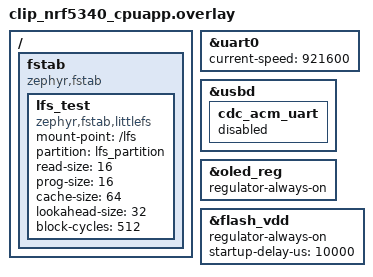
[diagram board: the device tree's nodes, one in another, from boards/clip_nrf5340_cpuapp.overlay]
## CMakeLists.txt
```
#
# Copyright (c) 2022 Nordic Semiconductor ASA
#
# SPDX-License-Identifier: LicenseRef-Nordic-5-Clause
#

cmake_minimum_required(VERSION 3.20.0)

# The test uses the repository's custom gpio-button devicetree binding.
list(APPEND DTS_ROOT ${CMAKE_CURRENT_LIST_DIR}/../..)

find_package(Zephyr REQUIRED HINTS $ENV{ZEPHYR_BASE})
project(clip)

target_sources(app PRIVATE
	src/main.c
	src/ble.c
	src/wifi.c
	src/button.c
	src/sdcard.c
	src/mic.c
	src/oled.c
	src/pmic.c
	src/motor.c
	src/usb.c
	src/identity.c
	src/flash_test.c
	src/sn_prog.c
	src/swd_ctrl.c
	# The test image builds the CH1115 driver directly. CONFIG_OLED_DISPLAY is
	# deliberately disabled in prj.conf to prevent the module from adding the
	# same source a second time.
	${CMAKE_CURRENT_LIST_DIR}/../../drivers/display/ch1115.c
)
```

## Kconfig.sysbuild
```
#
# Copyright (c) 2023 Nordic Semiconductor
#
# SPDX-License-Identifier: LicenseRef-Nordic-5-Clause
#

source "${ZEPHYR_BASE}/share/sysbuild/Kconfig"

config NRF_DEFAULT_IPC_RADIO
	default y

config NETCORE_IPC_RADIO_BT_HCI_IPC
	default y
```

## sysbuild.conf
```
#
# Copyright (c) 2024 Nordic Semiconductor ASA
#
# SPDX-License-Identifier: LicenseRef-Nordic-5-Clause
#

# Enable WiFi nRF70
SB_CONFIG_WIFI_NRF70=y
```

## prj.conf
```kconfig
#
# Copyright (c) 2023 Nordic Semiconductor ASA
#
# SPDX-License-Identifier: LicenseRef-Nordic-5-Clause
#

# DMIC (Digital Microphone)
CONFIG_AUDIO=y
CONFIG_AUDIO_DMIC=y

# SD Card and File System
CONFIG_DISK_ACCESS=y
CONFIG_DISK_DRIVER_SDMMC=y
CONFIG_FILE_SYSTEM=y
CONFIG_FAT_FILESYSTEM_ELM=y
CONFIG_FS_FATFS_LFN=y
CONFIG_FS_FATFS_MKFS=y
CONFIG_FILE_SYSTEM_MKFS=y

# SPI Flash
CONFIG_FLASH=y
CONFIG_FLASH_MAP=y

# WiFi AP mode
CONFIG_WIFI=y
CONFIG_WIFI_NRF70=y
CONFIG_NRF70_AP_MODE=y
CONFIG_WIFI_NM_WPA_SUPPLICANT=y
CONFIG_WIFI_NM_WPA_SUPPLICANT_AP=y
CONFIG_WIFI_NM_WPA_SUPPLICANT_LOG_LEVEL_INF=n
CONFIG_WIFI_RANDOM_MAC_ADDRESS=y

# WiFi and BLE coexistence
CONFIG_NRF70_SR_COEX=y
CONFIG_NRF_WIFI_IF_AUTO_START=n
CONFIG_NRF70_QSPI_LOW_POWER=y

# WiFi ready callback (for runtime net_if_up)
CONFIG_WIFI_READY_LIB=y

# Shared antenna configuration (not separate antennas)
CONFIG_COEX_SEP_ANTENNAS=n

# SR protocol is BLE
CONFIG_SR_PROTOCOL_BLE=y

# Reduce memory usage - fewer buffers
CONFIG_NRF70_RX_NUM_BUFS=8
CONFIG_NRF70_MAX_TX_AGGREGATION=2

# WiFi credentials - not needed for AP mode
CONFIG_WIFI_CREDENTIALS=n

# Disable WPA3/SAE - WPA2-PSK only (v3.3.0: WPA3 is now a choice)
CONFIG_WIFI_NM_WPA_SUPPLICANT_WPA3_IMPLEMENTATION_NONE=y

# WiFi memory
CONFIG_NRF_WIFI_CTRL_HEAP_SIZE=20000
CONFIG_NRF_WIFI_DATA_HEAP_SIZE=53000
CONFIG_WIFI_NM_WPA_SUPPLICANT_THREAD_STACK_SIZE=10240

# zperf for throughput testing
CONFIG_NET_ZPERF=y

# Networking Management API
CONFIG_NET_MGMT=y
CONFIG_NET_MGMT_EVENT=y

# AP static IP
CONFIG_NET_CONFIG_SETTINGS=y
CONFIG_NET_CONFIG_INIT_TIMEOUT=0
CONFIG_NET_CONFIG_MY_IPV4_ADDR="192.168.4.1"
CONFIG_NET_CONFIG_MY_IPV4_NETMASK="255.255.255.0"
CONFIG_NET_CONFIG_MY_IPV4_GW="192.168.4.1"

# DHCP server for AP clients
CONFIG_NET_DHCPV4=y
CONFIG_NET_DHCPV4_SERVER=y
CONFIG_NET_DHCPV4_SERVER_ADDR_COUNT=1

# Shell - minimal
CONFIG_SHELL=y
CONFIG_SHELL_BACKEND_SERIAL=y
CONFIG_NET_SHELL=n
CONFIG_WIFI_CREDENTIALS_SHELL=n
CONFIG_NET_L2_WIFI_SHELL=n

# Filesystem shell commands
CONFIG_FILE_SYSTEM_SHELL=y

# Regulator shell commands
# (CONFIG_FLASH_SHELL intentionally off: it registers a built-in `flash` root
#  command that collides with flash_test.c's `flash`/`flash speed`/`flash test`.)
CONFIG_REGULATOR=y
CONFIG_REGULATOR_SHELL=y
CONFIG_GPIO_SHELL=y

# Device power management
CONFIG_PM_DEVICE=y
CONFIG_PM_DEVICE_RUNTIME=y
CONFIG_TICKLESS_KERNEL=y
CONFIG_POWEROFF=y

# Sensor (for PMIC battery/charger monitoring)
CONFIG_SENSOR=y

# nRF Fuel Gauge: use the same profiled rechargeable-cell model as the
# production Clip firmware rather than a voltage-only lookup table.
CONFIG_NRF_FUEL_GAUGE=y
CONFIG_NRF_FUEL_GAUGE_VARIANT_SECONDARY_CELL=y

# Persist the fuel-gauge state on external-flash LittleFS. This keeps the
# displayed SoC continuous through reset / SYSTEM OFF instead of re-estimating
# it from a relaxed battery voltage on every boot.
CONFIG_FILE_SYSTEM_LITTLEFS=y
CONFIG_FS_LITTLEFS_FMP_DEV=y
CONFIG_FS_LITTLEFS_FC_HEAP_SIZE=4096
CONFIG_FS_LITTLEFS_NUM_FILES=16
CONFIG_FS_LITTLEFS_NUM_DIRS=4
CONFIG_SETTINGS=y
CONFIG_SETTINGS_FILE=y
CONFIG_SETTINGS_FILE_PATH="/lfs/settings/run"
CONFIG_SETTINGS_FILE_MAX_LINES=16


# I2C and I2C shell commands
CONFIG_I2C=y
CONFIG_I2C_SHELL=y

# Shell stack size - increased for WiFi operations
CONFIG_SHELL_STACK_SIZE=4096

# Logging - increased buffer to prevent message drops
CONFIG_LOG=y
CONFIG_LOG_DEFAULT_LEVEL=3
CONFIG_LOG_BACKEND_UART=y
CONFIG_LOG_BACKEND_RTT=n
CONFIG_LOG_BUFFER_SIZE=4096

# System settings
CONFIG_NEWLIB_LIBC=y
CONFIG_NEWLIB_LIBC_NANO=n

# Minimal networking - UDP only
CONFIG_NETWORKING=y
CONFIG_NET_SOCKETS=y
CONFIG_NET_SOCKETS_POLL_MAX=4
CONFIG_NET_L2_ETHERNET=y
CONFIG_NET_L2_WIFI_MGMT=y
CONFIG_NET_IPV4=y
CONFIG_NET_IPV6=n
CONFIG_NET_UDP=y
CONFIG_NET_TCP=n

# mbedTLS - use nRF security library instead of builtin
CONFIG_MBEDTLS=y
CONFIG_MBEDTLS_LEGACY_CRYPTO_C=n

# Memory optimization - reduced for RAM efficiency
CONFIG_SYSTEM_WORKQUEUE_STACK_SIZE=6144
CONFIG_MAIN_STACK_SIZE=6144

# Heap size for WiFi/crypto operations
CONFIG_HEAP_MEM_POOL_SIZE=120000

CONFIG_MBEDTLS_HEAP_SIZE=1024

# Network buffers (balanced for stability)
CONFIG_NET_TC_TX_COUNT=2
CONFIG_NET_BUF_TX_COUNT=14
CONFIG_NET_BUF_RX_COUNT=14
CONFIG_NET_PKT_TX_COUNT=6
CONFIG_NET_PKT_RX_COUNT=6
CONFIG_NET_TX_STACK_SIZE=4096
CONFIG_NET_RX_STACK_SIZE=4096

CONFIG_NET_BUF_FIXED_DATA_SIZE=y
CONFIG_NET_BUF_DATA_SIZE=512

# DHCP
CONFIG_NET_DHCPV4=y

CONFIG_WIFI_RANDOM_MAC_ADDRESS=y
CONFIG_BT=y
CONFIG_BT_PERIPHERAL=y
CONFIG_BT_DEVICE_NAME="Clip_Test"
CONFIG_BT_DEVICE_NAME_DYNAMIC=y
CONFIG_BT_MAX_CONN=1
CONFIG_BT_SMP=y
CONFIG_BT_GATT_CLIENT=y

# BLE throughput optimization
CONFIG_BT_BUF_ACL_RX_SIZE=251
CONFIG_BT_BUF_ACL_TX_SIZE=251
CONFIG_BT_L2CAP_TX_MTU=247

# Increase thread priority for BLE operations
CONFIG_BT_RX_STACK_SIZE=2048

# Display support (OLED CH1115)
CONFIG_DISPLAY=y
CONFIG_GPIO=y
# The test CMakeLists compiles this custom driver explicitly. Do not also
# compile the module library, otherwise ch1115.c is linked twice.
CONFIG_OLED_DISPLAY=n

# USB Mass Storage (expose SD card as USB drive)
CONFIG_USB_DEVICE_STACK_NEXT=y
CONFIG_USBD_MSC_CLASS=y
CONFIG_USBD_MSC_LUNS_PER_INSTANCE=1
CONFIG_USBD_MSC_DOUBLE_BUFFERING=n
CONFIG_USBD_MSC_SCSI_BUFFER_SIZE=512
CONFIG_HWINFO=y

# Reboot command
CONFIG_REBOOT=y

# SN programming tool CRC (sn_prog.c)
CONFIG_CRC=y
```

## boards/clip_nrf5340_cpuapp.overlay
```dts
/*
 * Copyright (c) 2023 Nordic Semiconductor ASA
 *
 * SPDX-License-Identifier: LicenseRef-Nordic-5-Clause
 */

/* UART configuration for 921600 baud rate */
&uart0 {
	current-speed = <921600>;
};

/* Enable USB device for MSC only */
&usbd {
	status = "okay";
	cdc_acm_uart {
		status = "disabled";
	};
};

/* The CH1115 driver has no vin-supply phandle. Keep its GPIO supply asserted
 * for the entire hardware-test session so it cannot be disabled as an unused
 * regulator before the persistent battery screen starts updating. */
&oled_reg {
	regulator-always-on;
};

/* SPI flash power (P0.27). With CONFIG_PM_DEVICE_RUNTIME the boot-on regulator
 * gets runtime-suspended before spi_nor probes the chip -> JEDEC read fails ->
 * "SPI flash not ready" + LittleFS mount fails (-19). Keep it asserted for the
 * whole test session. */
&flash_vdd {
	regulator-always-on;
	/* Unlike applications/clip (which runs under MCUboot, and MCUboot reads
	 * the app image from this flash so the chip is already powered/settled by
	 * the time the app probes it), this no-MCUboot image probes the flash at
	 * boot within microseconds of asserting VDD -> JEDEC read returns 00 00 00
	 * (chip still in power-on reset, tPUW ~10 ms). Wait it out. */
	startup-delay-us = <10000>;
};

/ {
	/* Point the generic filesystem shell at the external LittleFS partition.
	 * The test image has Partition Manager disabled, so its partition node is
	 * named lfs_partition (the production PM-generated alias is unavailable). */
	fstab {
		compatible = "zephyr,fstab";

		lfs_test: lfs_test {
			compatible = "zephyr,fstab,littlefs";
			mount-point = "/lfs";
			partition = <&lfs_partition>;
			read-size = <16>;
			prog-size = <16>;
			cache-size = <64>;
			lookahead-size = <32>;
			block-cycles = <512>;
		};
	};
};
```

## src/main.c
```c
/*
 * Copyright (c) 2023 Nordic Semiconductor ASA
 *
 * SPDX-License-Identifier: LicenseRef-Nordic-5-Clause
 */

#include <stdio.h>
#include <stdlib.h>
#include <zephyr/kernel.h>
#include <zephyr/logging/log.h>
#include <zephyr/sys/printk.h>
#include <zephyr/sys/reboot.h>
#include <zephyr/sys/poweroff.h>
#include <zephyr/shell/shell.h>
#include <zephyr/device.h>
#include <zephyr/drivers/gpio.h>
#include <zephyr/drivers/regulator.h>
#include <zephyr/pm/device.h>
#include <zephyr/storage/disk_access.h>
#include <zephyr/bluetooth/bluetooth.h>
#include <zephyr/dt-bindings/regulator/npm13xx.h>
#include <nrfx_clock.h>
#include <hal/nrf_oscillators.h>
#include "wifi.h"
#include "ble.h"
#include "button.h"
#include "sdcard.h"
#include "mic.h"
#include "oled.h"
#include "pmic.h"
#include "motor.h"
#include "usb.h"

LOG_MODULE_REGISTER(main, LOG_LEVEL_INF);

/* This image has no MCUboot (SB_CONFIG_BOOTLOADER_NONE), unlike applications/
 * clip where MCUboot accesses the external SPI flash first and so has already
 * driven flash_vdd high + woken the chip before the app probes it. Here
 * spi_nor (POST_KERNEL prio 80) is the first access, and with
 * CONFIG_PM_DEVICE_RUNTIME_ASYNC the boot-on regulator enable is deferred, so
 * the GPIO hasn't been driven yet -> JEDEC read returns 00 00 00. Force the
 * regulator on and block long enough (tPUW ~10 ms) for the chip to settle,
 * BEFORE spi_nor runs. */
static int flash_vdd_preinit(void)
{
	const struct device *fv = DEVICE_DT_GET(DT_NODELABEL(flash_vdd));
	if (device_is_ready(fv)) {
		(void)regulator_enable(fv);
	}
	k_msleep(50);
	return 0;
}
SYS_INIT(flash_vdd_preinit, POST_KERNEL, 78);

static int cmd_reboot(const struct shell *sh, size_t argc, char **argv)
{
	ARG_UNUSED(argc);
	ARG_UNUSED(argv);

	shell_print(sh, "Rebooting...");
	(void)pmic_battery_state_save();
	k_sleep(K_MSEC(100));
	sys_reboot(SYS_REBOOT_WARM);
	return 0;
}

SHELL_CMD_REGISTER(reboot, NULL, "Reboot device", cmd_reboot);

struct sd_shutdown_result {
	int unmount_rc;
	int deinit_rc;
	int suspend_rc;
	int cs_rc;
	int ldo_rc;
	bool ldo_before;
	bool ldo_after;
};

static struct sd_shutdown_result sys_sd_shutdown(void);
static void sys_wifi_power_off(void);

/* The fuel gauge is software state. Save it before any SYSTEM OFF path so a
 * relaxed cell voltage after wake cannot make the always-on OLED jump. */
static void sys_poweroff_with_battery_state(void)
{
	int ret = pmic_battery_state_save();

	if (ret != 0 && ret != -EAGAIN) {
		LOG_WRN("Fuel-gauge state save before power-off failed: %d", ret);
	}
	sys_poweroff();
}

/* cmd_sys_stop is defined after the device pointers below (it touches all of
 * them for a full shutdown). */

/* Isolate the UART contribution before SYSTEM OFF. The production Clip build
 * saves about 570 uA by disabling UART console/logging. */
static const struct device *const uart0 = DEVICE_DT_GET(DT_NODELABEL(uart0));

static int cmd_sys_uart_stop(const struct shell *sh, size_t argc, char **argv)
{
	ARG_UNUSED(argc);
	ARG_UNUSED(argv);

	shell_print(sh, "Suspending UARTE, then entering nRF5340 SYSTEM OFF");
	k_sleep(K_MSEC(100));
	(void)pm_device_action_run(uart0, PM_DEVICE_ACTION_SUSPEND);
	sys_poweroff_with_battery_state();
	return 0;
}

/* nRF7002 is powered by two board GPIOs; leave all data/coexistence pins
 * untouched here so this command isolates only the radio supply domains. */
static const struct device *const gpio0 = DEVICE_DT_GET(DT_NODELABEL(gpio0));
static const struct device *const gpio1 = DEVICE_DT_GET(DT_NODELABEL(gpio1));
static const struct device *const i2c2 = DEVICE_DT_GET(DT_NODELABEL(i2c2));
static const struct device *const spi4 = DEVICE_DT_GET(DT_NODELABEL(spi4));
static const struct device *const npm1300 = DEVICE_DT_GET(DT_NODELABEL(npm1300));
static const struct device *const npm1300_regulators =
	DEVICE_DT_GET(DT_NODELABEL(npm1300_regulators));
static const struct device *const ldo1 = DEVICE_DT_GET(DT_NODELABEL(npm1300_ldo1));
static const struct device *const ldo2 = DEVICE_DT_GET(DT_NODELABEL(npm1300_ldo2));

/* nRF7002 supply domains: this is the same proven isolation sequence used by
 * `sys wifi_stop`, which removes about 70 uA before SYSTEM OFF. */
static void sys_wifi_power_off(void)
{
	(void)gpio_pin_configure(gpio0, 11, GPIO_OUTPUT_INACTIVE); /* BUCKEN */
	(void)gpio_pin_configure(gpio0, 26, GPIO_OUTPUT_INACTIVE); /* IOVDD_EN */
	(void)gpio_pin_configure(gpio0, 29, GPIO_OUTPUT_INACTIVE); /* RF switch */
}

/* Keep every SD signal benign before cutting VDD_SD. SPI4's sleep pinctrl
 * parks SCK/MOSI/MISO low, and CS is then explicitly pulled low. */
static struct sd_shutdown_result sys_sd_shutdown(void)
{
	struct sd_shutdown_result result;

	result.ldo_before = regulator_is_enabled(ldo2);
	result.unmount_rc = sdcard_unmount();
	result.deinit_rc = disk_access_ioctl("SD", DISK_IOCTL_CTRL_DEINIT, NULL);
	result.suspend_rc = pm_device_action_run(spi4, PM_DEVICE_ACTION_SUSPEND);
	result.cs_rc = gpio_pin_configure(gpio0, 9, GPIO_INPUT | GPIO_PULL_DOWN);
	result.ldo_rc = regulator_disable(ldo2);
	result.ldo_after = regulator_is_enabled(ldo2);

	return result;
}

static void print_device_state(const struct shell *sh, const char *name,
			       const struct device *dev)
{
	shell_print(sh, "%s: ready=%d init=%d init_res=-%u", name,
		    device_is_ready(dev), dev->state->initialized, dev->state->init_res);
}

static int cmd_sys_sd_status(const struct shell *sh, size_t argc, char **argv)
{
	ARG_UNUSED(argc);
	ARG_UNUSED(argv);

	print_device_state(sh, "nPM1300", npm1300);
	print_device_state(sh, "nPM1300 regulators", npm1300_regulators);
	print_device_state(sh, "LDO1", ldo1);
	print_device_state(sh, "LDO2", ldo2);
	print_device_state(sh, "SPI4", spi4);
	return 0;
}

static int cmd_sys_sd_stop(const struct shell *sh, size_t argc, char **argv)
{
	struct sd_shutdown_result result;

	ARG_UNUSED(argc);
	ARG_UNUSED(argv);

	result = sys_sd_shutdown();

	shell_print(sh, "SD shutdown: ldo %d -> %d", result.ldo_before, result.ldo_after);
	shell_print(sh, "  unmount=%d deinit=%d spi4_suspend=%d cs=%d ldo2_disable=%d",
		    result.unmount_rc, result.deinit_rc, result.suspend_rc,
		    result.cs_rc, result.ldo_rc);
	shell_print(sh, "Entering nRF5340 SYSTEM OFF");
	k_sleep(K_MSEC(200));
	sys_poweroff_with_battery_state();
	return 0;
}

static int cmd_sys_wifi_stop(const struct shell *sh, size_t argc, char **argv)
{
	ARG_UNUSED(argc);
	ARG_UNUSED(argv);

	shell_print(sh, "Cutting nRF7002 power, then entering nRF5340 SYSTEM OFF");
	k_sleep(K_MSEC(100));
	sys_wifi_power_off();
	sys_poweroff_with_battery_state();
	return 0;
}

static int cmd_sys_oled_stop(const struct shell *sh, size_t argc, char **argv)
{
	ARG_UNUSED(argc);
	ARG_UNUSED(argv);

	shell_print(sh, "Isolating OLED bus, cutting VDD, then entering SYSTEM OFF");
	k_sleep(K_MSEC(100));
	/* Do not leave any OLED input high when VDD is removed: it back-powers
	 * the display through its ESD diodes. */
	(void)pm_device_action_run(i2c2, PM_DEVICE_ACTION_SUSPEND);
	(void)gpio_pin_configure(gpio1, 9, GPIO_OUTPUT_INACTIVE); /* RESET asserted */
	(void)gpio_pin_configure(gpio1, 8, GPIO_OUTPUT_INACTIVE); /* OLED VDD */
	sys_poweroff_with_battery_state();
	return 0;
}

static int cmd_sys_mic_stop(const struct shell *sh, size_t argc, char **argv)
{
	int ret;

	ARG_UNUSED(argc);
	ARG_UNUSED(argv);

	if (!device_is_ready(ldo1)) {
		shell_error(sh, "nPM1300 LDO1 is not ready");
		return -ENODEV;
	}

	shell_print(sh, "Cutting microphone LDO1, then entering SYSTEM OFF");
	ret = regulator_disable(ldo1);
	if (ret != 0) {
		shell_error(sh, "LDO1 disable failed: %d", ret);
		return ret;
	}

	k_sleep(K_MSEC(100));
	sys_poweroff_with_battery_state();
	return 0;
}

static int cmd_sys_ble_stop(const struct shell *sh, size_t argc, char **argv)
{
	int ret;

	ARG_UNUSED(argc);
	ARG_UNUSED(argv);

	shell_print(sh, "Stopping BLE, then entering nRF5340 SYSTEM OFF");
	ret = bt_le_adv_stop();
	if (ret != 0 && ret != -EALREADY) {
		shell_warn(sh, "BLE advertising stop failed: %d", ret);
	}

	ret = bt_disable();
	if (ret != 0) {
		/* The IPC controller may already be unavailable. Do not let a failed
		 * HCI reset prevent the following SYSTEM OFF current measurement. */
		shell_warn(sh, "BLE disable failed: %d; continuing to SYSTEM OFF", ret);
	}

	k_sleep(K_MSEC(100));
	sys_poweroff_with_battery_state();
	return 0;
}

static const struct device *const buck2 = DEVICE_DT_GET(DT_NODELABEL(npm1300_buck2));

static int cmd_sys_buck_pfm_stop(const struct shell *sh, size_t argc, char **argv)
{
	int ret;

	ARG_UNUSED(argc);
	ARG_UNUSED(argv);

	if (!device_is_ready(buck2)) {
		shell_error(sh, "nPM1300 BUCK2 is not ready");
		return -ENODEV;
	}

	shell_print(sh, "Setting BUCK2 PFM, then entering SYSTEM OFF");
	ret = regulator_set_mode(buck2, NPM13XX_BUCK_MODE_PFM);
	if (ret != 0) {
		shell_error(sh, "BUCK2 PFM failed: %d", ret);
		return ret;
	}

	k_sleep(K_MSEC(100));
	sys_poweroff_with_battery_state();
	return 0;
}

/* Full shutdown: stop every peripheral known to leak or hold a wake source,
 * THEN suspend the UART (~570 uA console leak) and enter SYSTEM OFF. Use this
 * (not the single-peripheral `sys *_stop` isolation commands) to measure sleep
 * current. NOTE: with SWD/J-Link attached, nRF5340 cannot enter true SYSTEM
 * OFF — detach the probe and power-cycle to read uA-level current. */
static int cmd_sys_stop(const struct shell *sh, size_t argc, char **argv)
{
	struct sd_shutdown_result sd;
	int ret;

	ARG_UNUSED(argc);
	ARG_UNUSED(argv);

	shell_print(sh, "Full peripheral shutdown, then nRF5340 SYSTEM OFF");

	/* 1. Stop the 1 s battery/OLED refresh work — otherwise it keeps waking
	 * the CPU every second and writing to the bus/display being shut down. */
	shell_print(sh, "  [1/9] Stop 1s battery/OLED refresh work: %d",
		    pmic_display_work_stop());

	/* 2. BLE / network-core radio (wake source) */
	shell_print(sh, "  [2/9] BLE: adv stop + disable");
	ret = bt_le_adv_stop();
	if (ret != 0 && ret != -EALREADY) {
		shell_warn(sh, "    adv stop: %d", ret);
	}
	(void)bt_disable();

	/* 3. nRF7002 WiFi supply (~70 uA) */
	shell_print(sh, "  [3/9] WiFi: nRF7002 power off");
	sys_wifi_power_off();

	/* 4. USB device (wake source when VBUS present) */
	shell_print(sh, "  [4/9] USB: disable");
	(void)usb_msc_disable();

	/* 5. SD card + LDO2 */
	shell_print(sh, "  [5/9] SD: unmount + SPI4 suspend + LDO2 off");
	sd = sys_sd_shutdown();
	if (sd.ldo_after) {
		shell_warn(sh, "    LDO2 still on (unmount=%d deinit=%d spi4=%d cs=%d ldo=%d)",
			   sd.unmount_rc, sd.deinit_rc, sd.suspend_rc, sd.cs_rc, sd.ldo_rc);
	}

	/* 6. Mic LDO1 */
	shell_print(sh, "  [6/9] Mic: LDO1 off");
	if (device_is_ready(ldo1)) {
		(void)regulator_disable(ldo1);
	}

	/* 7. OLED (bus suspend + VDD/RESET low to avoid ESD back-power) */
	shell_print(sh, "  [7/9] OLED: bus suspend + VDD off");
	(void)pm_device_action_run(i2c2, PM_DEVICE_ACTION_SUSPEND);
	(void)gpio_pin_configure(gpio1, 9, GPIO_OUTPUT_INACTIVE);  /* RESET */
	(void)gpio_pin_configure(gpio1, 8, GPIO_OUTPUT_INACTIVE);  /* OLED VDD */

	/* 8. BUCK2 PFM (low-power regulator mode) */
	shell_print(sh, "  [8/9] BUCK2: PFM");
	if (device_is_ready(buck2)) {
		(void)regulator_set_mode(buck2, NPM13XX_BUCK_MODE_PFM);
	}

	/* 9. UART console (~570 uA) — suspended LAST so the shell stays up until
	 * the final message is flushed. */
	shell_print(sh, "  [9/9] UART: suspend (console goes dark) -> SYSTEM OFF");
	k_sleep(K_MSEC(300));  /* let the last line flush before UARTE dies */
	(void)pm_device_action_run(uart0, PM_DEVICE_ACTION_SUSPEND);

	sys_poweroff_with_battery_state();
	return 0;
}

SHELL_STATIC_SUBCMD_SET_CREATE(sub_sys_cmds,
	SHELL_CMD(stop, NULL, "Full shutdown (all peripherals) then SYSTEM OFF", cmd_sys_stop),
	SHELL_CMD(uart_stop, NULL, "Suspend UARTE then system power off", cmd_sys_uart_stop),
	SHELL_CMD(wifi_stop, NULL, "Cut nRF7002 power then system power off", cmd_sys_wifi_stop),
	SHELL_CMD(oled_stop, NULL, "Cut OLED VDD then system power off", cmd_sys_oled_stop),
	SHELL_CMD(mic_stop, NULL, "Cut microphone LDO1 then system power off", cmd_sys_mic_stop),
	SHELL_CMD(ble_stop, NULL, "Stop BLE then system power off", cmd_sys_ble_stop),
	SHELL_CMD(buck_pfm_stop, NULL, "Set BUCK2 PFM then system power off", cmd_sys_buck_pfm_stop),
	SHELL_CMD(sd_status, NULL, "Show SD/PMIC device initialization state", cmd_sys_sd_status),
	SHELL_CMD(sd_stop, NULL, "Log SD shutdown steps then system power off", cmd_sys_sd_stop),
);

SHELL_CMD_REGISTER(sys, &sub_sys_cmds, "System power control", NULL);

/* LFXO capacitance commands */
static const char *lfxo_cap_name(uint32_t val)
{
	switch (val) {
	case 0: return "External";
	case 1: return "6 pF";
	case 2: return "7 pF";
	case 3: return "9 pF";
	default: return "Unknown";
	}
}

static int cmd_lfxo_cap_get(const struct shell *sh, size_t argc, char **argv)
{
	ARG_UNUSED(argc);
	ARG_UNUSED(argv);

	uint32_t cap = NRF_OSCILLATORS->XOSC32KI.INTCAP;
	shell_print(sh, "LFXO capacitance: %u (%s)", cap, lfxo_cap_name(cap));
	return 0;
}

static int cmd_lfxo_cap_set(const struct shell *sh, size_t argc, char **argv)
{
	if (argc < 2) {
		shell_print(sh, "Usage: lfxo cap <0-3>");
		shell_print(sh, "  0 = External capacitors");
		shell_print(sh, "  1 = 6 pF internal");
		shell_print(sh, "  2 = 7 pF internal");
		shell_print(sh, "  3 = 9 pF internal");
		return -EINVAL;
	}

	int val = atoi(argv[1]);
	if (val < 0 || val > 3) {
		shell_print(sh, "Error: value must be 0-3");
		return -EINVAL;
	}

	NRF_OSCILLATORS->XOSC32KI.INTCAP = (uint32_t)val;
	shell_print(sh, "LFXO capacitance set to: %u (%s)", val, lfxo_cap_name(val));
	return 0;
}

SHELL_STATIC_SUBCMD_SET_CREATE(sub_lfxo_cap,
	SHELL_CMD(get, NULL, "Get LFXO capacitance", cmd_lfxo_cap_get),
	SHELL_CMD_ARG(set, NULL, "Set LFXO capacitance (0-3)", cmd_lfxo_cap_set, 2, 0),
	SHELL_SUBCMD_SET_END
);

SHELL_CMD_REGISTER(lfxo, &sub_lfxo_cap, "LFXO 32.768kHz crystal capacitance", NULL);

/* HFXO capacitance commands */
static int cmd_hfxo_cap_get(const struct shell *sh, size_t argc, char **argv)
{
	ARG_UNUSED(argc);
	ARG_UNUSED(argv);

	uint32_t reg = NRF_OSCILLATORS->XOSC32MCAPS;
	bool enabled = (reg & OSCILLATORS_XOSC32MCAPS_ENABLE_Msk) != 0;
	uint32_t capvalue = (reg & OSCILLATORS_XOSC32MCAPS_CAPVALUE_Msk)
		>> OSCILLATORS_XOSC32MCAPS_CAPVALUE_Pos;

	if (enabled) {
		shell_print(sh, "HFXO capacitance: internal (CAPVALUE=%u)", capvalue);
	} else {
		shell_print(sh, "HFXO capacitance: external");
	}
	return 0;
}

static int cmd_hfxo_cap_set(const struct shell *sh, size_t argc, char **argv)
{
	if (argc < 2) {
		shell_print(sh, "Usage: hfxo set <picofarad>");
		shell_print(sh, "  Range: 7.0 - 20.0 pF, step 0.5 pF");
		shell_print(sh, "  Example: hfxo set 9.5");
		shell_print(sh, "  Use 0 to disable (external capacitors)");
		return -EINVAL;
	}

	float pf = strtof(argv[1], NULL);
	if (pf == 0.0f) {
		NRF_OSCILLATORS->XOSC32MCAPS =
			OSCILLATORS_XOSC32MCAPS_ENABLE_Disabled <<
			OSCILLATORS_XOSC32MCAPS_ENABLE_Pos;
		shell_print(sh, "HFXO capacitance: external");
		return 0;
	}

	if (pf < 7.0f || pf > 20.0f) {
		shell_print(sh, "Error: value must be 7.0-20.0 pF or 0 for external");
		return -EINVAL;
	}

	uint32_t capvalue = NRF_OSCILLATORS_HFXO_CAP_CALCULATE(NRF_FICR, pf);
	NRF_OSCILLATORS->XOSC32MCAPS =
		(OSCILLATORS_XOSC32MCAPS_ENABLE_Enabled <<
		 OSCILLATORS_XOSC32MCAPS_ENABLE_Pos) |
		(capvalue << OSCILLATORS_XOSC32MCAPS_CAPVALUE_Pos);
	shell_print(sh, "HFXO capacitance set to: %.1f pF (CAPVALUE=%u)", (double)pf, capvalue);
	return 0;
}

SHELL_STATIC_SUBCMD_SET_CREATE(sub_hfxo,
	SHELL_CMD(get, NULL, "Get HFXO capacitance", cmd_hfxo_cap_get),
	SHELL_CMD_ARG(set, NULL, "Set HFXO capacitance in pF (7.0-20.0, 0=external)",
		      cmd_hfxo_cap_set, 2, 0),
	SHELL_SUBCMD_SET_END
);

SHELL_CMD_REGISTER(hfxo, &sub_hfxo, "HFXO 32MHz crystal capacitance", NULL);

int main(void)
{
	int ret;

	printk("Starting %s with CPU frequency: %d MHz\n", CONFIG_BOARD, SystemCoreClock / 1000000);

	/* Initialize Button */
	ret = button_init();
	if (ret != 0) {
		LOG_ERR("Button initialization failed: %d", ret);
	}

	/* Initialize SD Card (auto-mounts if present) */
	ret = sdcard_init();
	if (ret != 0) {
		LOG_ERR("SD card initialization failed: %d", ret);
		/* Continue anyway, SD card is optional */
	}

	/* Initialize Microphone */
	ret = mic_init();
	if (ret != 0) {
		LOG_ERR("Microphone initialization failed: %d", ret);
		/* Continue anyway, MIC is optional */
	}

	/* Initialize OLED display */
	ret = oled_init();
	if (ret != 0) {
		LOG_ERR("OLED display initialization failed: %d", ret);
		/* Continue anyway, OLED is optional */
	} else {
		/* Make the battery screen visible immediately. PMIC initialization and
		 * its periodic refresh replace this placeholder with live readings. */
		oled_show_battery_unavailable();
	}

	/* Initialize PMIC (NPM1300) */
	ret = pmic_init();
	if (ret != 0) {
		LOG_ERR("PMIC initialization failed: %d", ret);
		/* Continue anyway, PMIC is optional for testing */
	}

	/* Initialize Motor */
	ret = motor_init();
	if (ret != 0) {
		LOG_ERR("Motor initialization failed: %d", ret);
		/* Continue anyway, Motor is optional for testing */
	}

	/* Initialize USB MSC */
	ret = usb_msc_init();
	if (ret != 0) {
		LOG_WRN("USB MSC initialization failed: %d", ret);
	}

	/* Initialize BLE - starts advertising automatically */
	ret = ble_init();
	if (ret != 0) {
		LOG_ERR("Bluetooth initialization failed: %d", ret);
		/* Continue anyway, BLE is optional */
	}

	/* Initialize WiFi */
	ret = wifi_run_test();
	if (ret != 0) {
		LOG_ERR("WiFi initialization failed: %d", ret);
		/* Continue anyway, WiFi can be configured via shell */
	}

	printk("System ready\n");
	printk("WiFi: Use 'wifi on' to start AP, 'wifi status' to check\n");
	printk("BLE: Advertising as '%s'\n", CONFIG_BT_DEVICE_NAME);
	printk("SD card: Use 'sd mount' to mount, 'fs ls /SD:' to list files\n");
	printk("Flash: Use 'flash' commands for SPI flash operations\n");
	printk("MIC: Use 'mic capture [time_sec]' to capture audio\n");
	printk("OLED: Use 'oled test' to run display tests, 'oled help' for more\n");
	printk("PMIC: Use 'pmic status' to check battery, 'pmic ship' to power off\n");
	printk("Motor: Use 'motor pulse' or 'motor pattern' to test vibration\n");
	printk("USB: Use 'usb msc on' to expose SD card, 'mic record' to record WAV\n");

	return 0;
}
```

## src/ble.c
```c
/*
 * Copyright (c) 2023 Nordic Semiconductor ASA
 *
 * SPDX-License-Identifier: LicenseRef-Nordic-5-Clause
 */

#include <zephyr/kernel.h>
#include <zephyr/logging/log.h>
#include <zephyr/shell/shell.h>
#include <zephyr/bluetooth/bluetooth.h>
#include <zephyr/bluetooth/hci.h>
#include <zephyr/bluetooth/hci_vs.h>
#include <zephyr/bluetooth/conn.h>
#include <zephyr/bluetooth/uuid.h>
#include <zephyr/bluetooth/gatt.h>
#include "ble.h"
#include <string.h>
#include "identity.h"

LOG_MODULE_REGISTER(ble, LOG_LEVEL_INF);

#define DEVICE_NAME CONFIG_BT_DEVICE_NAME
#define DEVICE_NAME_LEN (sizeof(DEVICE_NAME) - 1)

#define MTU_SIZE 247
#define NOTIFY_DATA_SIZE (MTU_SIZE - 3)  /* Account for opcode and handle */

/* GATT service declaration */
static const struct bt_uuid_128 svc_uuid = BT_UUID_INIT_128(
	BT_UUID_128_ENCODE(0x1234, 0x5678, 0x1234, 0x5678, 0x123456789abc));

static const struct bt_uuid_128 data_uuid = BT_UUID_INIT_128(
	BT_UUID_128_ENCODE(0x1234, 0x5678, 0x1234, 0x5678, 0x123456789abd));

/* Connection and notify state */
static struct bt_conn *current_conn;
static volatile bool notify_enabled;
static volatile bool mtu_exchanged;
static K_SEM_DEFINE(conn_sem, 0, 1);
static K_SEM_DEFINE(mtu_sem, 0, 1);

/* Throughput test data */
static uint8_t notify_data[NOTIFY_DATA_SIZE];
static uint64_t test_start_time;
static uint64_t total_bytes_sent;
static uint32_t packet_count;
static uint64_t last_stats_time;
static uint64_t last_stats_bytes;
static struct k_thread notify_thread;
static K_THREAD_STACK_DEFINE(notify_stack, 2048);

/* Advertising data.
 * ad[] is non-const: the name entry is updated at init to the per-device
 * runtime name (Clip_<suffix>) set via bt_set_name(). */
static struct bt_data ad[] = {
	BT_DATA_BYTES(BT_DATA_FLAGS, (BT_LE_AD_GENERAL | BT_LE_AD_NO_BREDR)),
	BT_DATA(BT_DATA_NAME_COMPLETE, DEVICE_NAME, DEVICE_NAME_LEN),
};

static const struct bt_data sd[] = {
	BT_DATA_BYTES(BT_DATA_UUID128_ALL,
		      0xBC, 0x9A, 0x78, 0x56, 0x34, 0x12, 0x78, 0x56,
		      0x34, 0x12, 0x78, 0x56, 0x34, 0x12, 0xAB, 0xCD),
};

/* Work queue for deferred operations */
static struct k_work adv_work;

/* Advertising restart work handler */
static void adv_work_handler(struct k_work *work)
{
	bt_le_adv_start(BT_LE_ADV_CONN_FAST_1, ad, ARRAY_SIZE(ad),
			sd, ARRAY_SIZE(sd));
}

/* Forward declarations */
static void notify_ccc_cfg_changed(const struct bt_gatt_attr *attr,
				    uint16_t value);
static ssize_t read_data(struct bt_conn *conn,
			 const struct bt_gatt_attr *attr,
			 void *buf, uint16_t len, uint16_t offset);

/* GATT attributes - using BT_GATT_SERVICE_DEFINE for compile-time registration */
BT_GATT_SERVICE_DEFINE(throughput_svc,
	BT_GATT_PRIMARY_SERVICE(&svc_uuid),
	BT_GATT_CHARACTERISTIC(&data_uuid.uuid,
			       BT_GATT_CHRC_READ | BT_GATT_CHRC_NOTIFY,
			       BT_GATT_PERM_READ,
			       read_data, NULL, NULL),
	BT_GATT_CCC(notify_ccc_cfg_changed,
		    BT_GATT_PERM_READ | BT_GATT_PERM_WRITE),
);

/* CCC callback - triggered when phone enables/disables notify */
static void notify_ccc_cfg_changed(const struct bt_gatt_attr *attr,
				    uint16_t value)
{
	bool notify = (value == BT_GATT_CCC_NOTIFY);

	if (notify != notify_enabled) {
		if (notify) {
			notify_enabled = true;

			/* Wait for MTU exchange to complete before starting */
			if (mtu_exchanged) {
				test_start_time = k_uptime_get();
				total_bytes_sent = 0;
				packet_count = 0;
				last_stats_time = test_start_time;
				last_stats_bytes = 0;
				k_wakeup(&notify_thread);
			}
		} else {
			uint64_t elapsed_ms = k_uptime_get() - test_start_time;
			uint32_t throughput_kbps = 0;

			notify_enabled = false;

			if (elapsed_ms > 0) {
				throughput_kbps = (uint32_t)((total_bytes_sent * 8) / elapsed_ms);
			}

			printk("\n=== BLE Throughput Test Results ===\n");
			printk("Packets sent: %u\n", packet_count);
			printk("Bytes sent: %llu\n", total_bytes_sent);
			printk("Time: %llu ms\n", elapsed_ms);
			printk("Throughput: %u kbps (%u.%03u Mbps)\n",
				throughput_kbps,
				throughput_kbps / 1000,
				throughput_kbps % 1000);
			printk("===================================\n");
		}
	}
}

/* Read callback (not used but required) */
static ssize_t read_data(struct bt_conn *conn,
			 const struct bt_gatt_attr *attr,
			 void *buf, uint16_t len, uint16_t offset)
{
	return bt_gatt_attr_read(conn, attr, buf, len, offset,
				 notify_data, sizeof(notify_data));
}

/* Notify thread - continuously sends data when notify is enabled */
static void notify_thread_func(void *p1, void *p2, void *p3)
{
	ARG_UNUSED(p1);
	ARG_UNUSED(p2);
	ARG_UNUSED(p3);

	while (1) {
		if (notify_enabled && current_conn && mtu_exchanged) {
			int err;
			uint64_t now;

			/* Check before sending */
			if (!notify_enabled) {
				break;
			}

			err = bt_gatt_notify(current_conn, &throughput_svc.attrs[2],
					     notify_data, sizeof(notify_data));
			if (err == 0) {
				total_bytes_sent += sizeof(notify_data);
				packet_count++;
			} else if (err == -ENOMEM || err == -EAGAIN) {
				/* Buffer full, wait and retry */
				k_sleep(K_MSEC(1));
				continue;
			} else if (err == -ENOTCONN) {
				notify_enabled = false;
				continue;
			}

			/* Print stats every second */
			now = k_uptime_get();
			if (now - last_stats_time >= 1000) {
				uint64_t bytes_delta = total_bytes_sent - last_stats_bytes;
				uint32_t rate_kbps = (bytes_delta * 8) / 1000;

				printk("BLE: %u kbps (%u.%03u Mbps), Total: %llu bytes\n",
				       rate_kbps, rate_kbps / 1000, rate_kbps % 1000,
				       total_bytes_sent);

				last_stats_time = now;
				last_stats_bytes = total_bytes_sent;
			}

			/* No delay - send as fast as possible, only wait on buffer full */
		} else {
			k_sleep(K_MSEC(10));
		}
	}
}

/* MTU exchange callback */
static void mtu_exchange_cb(struct bt_conn *conn, uint8_t err,
			     struct bt_gatt_exchange_params *params)
{
	if (!err) {
		mtu_exchanged = true;

		/* If notify was already enabled, start the test now */
		if (notify_enabled) {
			test_start_time = k_uptime_get();
			total_bytes_sent = 0;
			packet_count = 0;
			k_wakeup(&notify_thread);
		}
	}
	k_sem_give(&mtu_sem);
}

static struct bt_gatt_exchange_params mtu_params = {
	.func = mtu_exchange_cb,
};

/* Connection callbacks */
static void connected(struct bt_conn *conn, uint8_t err)
{
	if (err) {
		return;
	}

	current_conn = bt_conn_ref(conn);
	mtu_exchanged = false;

	/* Request MTU exchange */
	bt_gatt_exchange_mtu(conn, &mtu_params);

	k_sem_give(&conn_sem);
}

static void disconnected(struct bt_conn *conn, uint8_t reason)
{
	if (current_conn == conn) {
		bt_conn_unref(current_conn);
		current_conn = NULL;
		notify_enabled = false;
		k_sem_reset(&conn_sem);

		/* Schedule advertising restart via work queue */
		k_work_submit(&adv_work);
	}
}

static void le_param_updated(struct bt_conn *conn, uint16_t interval,
			     uint16_t latency, uint16_t timeout)
{
	/* Connection parameters updated - MTU exchange may complete here */
	mtu_exchanged = true;

	if (notify_enabled && test_start_time == 0) {
		test_start_time = k_uptime_get();
		total_bytes_sent = 0;
		packet_count = 0;
		k_wakeup(&notify_thread);
	}
}

static struct bt_conn_cb conn_callbacks = {
	.connected = connected,
	.disconnected = disconnected,
	.le_param_updated = le_param_updated,
};

int ble_init(void)
{
	int err;

	/* Initialize notification data pattern */
	for (size_t i = 0; i < sizeof(notify_data); i++) {
		notify_data[i] = i & 0xFF;
	}

	/* Initialize work queue for deferred operations */
	k_work_init(&adv_work, adv_work_handler);

	/* Enable Bluetooth */
	err = bt_enable(NULL);
	if (err) {
		return err;
	}

	/* Register connection callbacks */
	bt_conn_cb_register(&conn_callbacks);

	/* Per-device BLE name (Clip_<suffix>); the WiFi AP SSID uses the same
	 * suffix, so产测 can lock a board by name. Update the name AD to the
	 * runtime name (ad[] is non-const for this). */
	const char *id_name = identity_ble_name_get();
	bt_set_name(id_name);
	ad[1].data = id_name;
	ad[1].data_len = (uint8_t)strlen(id_name);

	/* Start advertising */
	err = bt_le_adv_start(BT_LE_ADV_CONN_FAST_1, ad, ARRAY_SIZE(ad),
			      sd, ARRAY_SIZE(sd));
	if (err) {
		return err;
	}

	/* Create notify thread with lower priority than main thread */
	k_thread_create(&notify_thread, notify_stack,
			K_THREAD_STACK_SIZEOF(notify_stack),
			notify_thread_func,
			NULL, NULL, NULL,
			K_PRIO_COOP(-1), 0, K_NO_WAIT);

	return 0;
}

/* BLE TX power shell command: set (dBm) for advertising and connections */
static int cmd_ble_txpower(const struct shell *sh, size_t argc, char **argv)
{
	struct net_buf *buf, *rsp;
	struct bt_hci_cp_vs_write_tx_power_level *cp;
	struct bt_hci_rp_vs_write_tx_power_level *rp;

	if (argc < 2) {
		shell_print(sh, "Usage: ble_txpower <dBm>");
		shell_print(sh, "nRF5340: -40, -20, -16, -12, -8, -4, 0, 3, 4, 5, 6, 7, 8");
		return -EINVAL;
	}

	int8_t power = (int8_t)atoi(argv[1]);

	/* Set TX power for advertising (handle_type=0, handle=0) */
	buf = bt_hci_cmd_create(BT_HCI_OP_VS_WRITE_TX_POWER_LEVEL, sizeof(*cp));
	if (!buf) {
		shell_error(sh, "Failed to create HCI cmd");
		return -ENOMEM;
	}
	cp = net_buf_add(buf, sizeof(*cp));
	cp->handle_type = BT_HCI_VS_LL_HANDLE_TYPE_ADV;
	cp->handle = 0;
	cp->tx_power_level = power;

	int ret = bt_hci_cmd_send_sync(BT_HCI_OP_VS_WRITE_TX_POWER_LEVEL, buf, &rsp);

	if (ret) {
		shell_error(sh, "Set TX power failed: %d", ret);
		return ret;
	}
	rp = (void *)rsp->data;
	shell_print(sh, "BLE TX power: requested %d dBm, selected %d dBm",
		    power, rp->selected_tx_power);
	net_buf_unref(rsp);

	/* Also set for active connection if any */
	if (current_conn) {
		uint16_t conn_handle = bt_conn_index(current_conn);

		buf = bt_hci_cmd_create(BT_HCI_OP_VS_WRITE_TX_POWER_LEVEL, sizeof(*cp));
		if (buf) {
			cp = net_buf_add(buf, sizeof(*cp));
			cp->handle_type = BT_HCI_VS_LL_HANDLE_TYPE_CONN;
			cp->handle = conn_handle;
			cp->tx_power_level = power;
			bt_hci_cmd_send_sync(BT_HCI_OP_VS_WRITE_TX_POWER_LEVEL, buf, &rsp);
			rp = (void *)rsp->data;
			shell_print(sh, "Conn TX power: selected %d dBm", rp->selected_tx_power);
			net_buf_unref(rsp);
		}
	}

	return 0;
}

SHELL_CMD_REGISTER(ble_txpower, NULL,
		   "Set BLE TX power (dBm)", cmd_ble_txpower);
```

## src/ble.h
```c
/*
 * Copyright (c) 2023 Nordic Semiconductor ASA
 *
 * SPDX-License-Identifier: LicenseRef-Nordic-5-Clause
 */

#ifndef BLE_H
#define BLE_H

/* Custom 128-bit UUID for throughput test service */
#define BT_UUID_THROUGHPUT_TEST \
	BT_UUID_DECLARE_128(BT_UUID_128_ENCODE(0x1234, 0x5678, 0x1234, 0x5678, 0x123456789abc))

/* Characteristic UUIDs */
#define BT_UUID_THROUGHPUT_DATA \
	BT_UUID_DECLARE_128(BT_UUID_128_ENCODE(0x1234, 0x5678, 0x1234, 0x5678, 0x123456789abd))

int ble_init(void);

#endif /* BLE_H */
```

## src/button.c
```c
/*
 * Copyright (c) 2023 Nordic Semiconductor ASA
 *
 * SPDX-License-Identifier: LicenseRef-Nordic-5-Clause
 */

#include <zephyr/kernel.h>
#include <zephyr/device.h>
#include <zephyr/drivers/gpio.h>
#include <zephyr/logging/log.h>
#include "button.h"
#include "oled.h"

LOG_MODULE_REGISTER(button, LOG_LEVEL_INF);

/* Get button from devicetree */
static const struct gpio_dt_spec button = GPIO_DT_SPEC_GET(DT_NODELABEL(usr_btn), gpios);
static struct gpio_callback button_cb_data;

/* Visual feedback on press: fill the OLED for ~1 s (the 1 s battery-display
 * refresh in pmic.c then restores the normal screen). Deferred to a work item
 * — the GPIO ISR can't touch I2C2. */
static struct k_work button_oled_work;
static void button_oled_flash_handler(struct k_work *work)
{
	ARG_UNUSED(work);
	oled_test_fill();
}

/* Button interrupt handler */
static void button_pressed(const struct device *dev, struct gpio_callback *cb, uint32_t pins)
{
	LOG_INF("Button pressed!");
	k_work_submit(&button_oled_work);
}

int button_init(void)
{
	int ret;

	LOG_INF("Initializing Button...");

	k_work_init(&button_oled_work, button_oled_flash_handler);

	/* Initialize button */
	if (!gpio_is_ready_dt(&button)) {
		LOG_ERR("Button device not ready");
		return -ENODEV;
	}

	ret = gpio_pin_configure_dt(&button, GPIO_INPUT);
	if (ret != 0) {
		LOG_ERR("Failed to configure button GPIO: %d", ret);
		return ret;
	}

	ret = gpio_pin_interrupt_configure_dt(&button, GPIO_INT_EDGE_TO_ACTIVE);
	if (ret != 0) {
		LOG_ERR("Failed to configure button interrupt: %d", ret);
		return ret;
	}

	gpio_init_callback(&button_cb_data, button_pressed, BIT(button.pin));
	gpio_add_callback(button.port, &button_cb_data);

	LOG_INF("Button ready on GPIO P0.%d - press to see log message", button.pin);

	return 0;
}
```

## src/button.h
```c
/*
 * Copyright (c) 2023 Nordic Semiconductor ASA
 *
 * SPDX-License-Identifier: LicenseRef-Nordic-5-Clause
 */

#ifndef BUTTON_H_
#define BUTTON_H_

#include <zephyr/kernel.h>

/**
 * @brief Initialize Button module
 *
 * @return 0 on success, negative errno code on failure
 */
int button_init(void);

#endif /* BUTTON_H_ */
```

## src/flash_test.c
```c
/*
 * Copyright (c) 2026 Seeed Technology Co., Ltd.
 *
 * SPDX-License-Identifier: LicenseRef-Nordic-5-Clause
 */

#include <zephyr/kernel.h>
#include <zephyr/device.h>
#include <zephyr/drivers/flash.h>
#include <zephyr/logging/log.h>
#include <zephyr/shell/shell.h>
#include <stdlib.h>
#include <string.h>

LOG_MODULE_REGISTER(flash_test, LOG_LEVEL_INF);

/* Keep the battery fuel-gauge settings in the LittleFS partition starting at
 * 0x130000 intact. The no-MCUboot hardware-test image does not use the two
 * external OTA slots, so reserve the 960 KB app slot for destructive raw
 * Flash testing instead. */
#define FLASH_TEST_OFFSET 0x000000
#define FLASH_TEST_MAX_SIZE (960 * 1024)
#define CHUNK_SIZE 4096

static int cmd_flash_speed(const struct shell *sh, size_t argc, char **argv)
{
	const struct device *flash_dev;
	uint32_t test_size = FLASH_TEST_MAX_SIZE;
	uint8_t *write_buf;
	uint8_t *read_buf;
	uint64_t start_time, end_time;
	int rc;

	flash_dev = DEVICE_DT_GET(DT_NODELABEL(spi_flash));
	if (!device_is_ready(flash_dev)) {
		shell_error(sh, "SPI flash not ready");
		return -ENODEV;
	}

	if (argc >= 2) {
		test_size = atoi(argv[1]) * 1024;
		if (test_size < CHUNK_SIZE) {
			test_size = CHUNK_SIZE;
		}
		if (test_size > FLASH_TEST_MAX_SIZE) {
			test_size = FLASH_TEST_MAX_SIZE;
		}
	}

	shell_print(sh, "Flash speed test (size: %u KB, offset: 0x%x)...",
		    test_size / 1024, FLASH_TEST_OFFSET);

	write_buf = k_malloc(CHUNK_SIZE);
	read_buf = k_malloc(CHUNK_SIZE);
	if (!write_buf || !read_buf) {
		shell_error(sh, "Failed to allocate buffers");
		k_free(write_buf);
		k_free(read_buf);
		return -ENOMEM;
	}

	/* Fill write buffer with pattern */
	for (uint32_t i = 0; i < CHUNK_SIZE; i++) {
		write_buf[i] = (uint8_t)(i & 0xFF);
	}

	/* Erase test */
	shell_print(sh, "Erasing %u KB...", test_size / 1024);
	start_time = k_uptime_get();
	for (uint32_t offset = 0; offset < test_size; offset += CHUNK_SIZE) {
		rc = flash_erase(flash_dev, FLASH_TEST_OFFSET + offset, CHUNK_SIZE);
		if (rc != 0) {
			shell_error(sh, "Erase failed at 0x%x: %d",
				    FLASH_TEST_OFFSET + offset, rc);
			goto cleanup;
		}
	}
	end_time = k_uptime_get();
	{
		uint64_t erase_time = end_time - start_time;
		uint32_t erase_speed = erase_time > 0 ?
			(test_size / 1024 * 1000) / erase_time : 0;
		shell_print(sh, "Erase: %llu ms, %u KB/s", erase_time, erase_speed);
	}

	/* Write test */
	shell_print(sh, "Writing %u KB...", test_size / 1024);
	start_time = k_uptime_get();
	for (uint32_t offset = 0; offset < test_size; offset += CHUNK_SIZE) {
		rc = flash_write(flash_dev, FLASH_TEST_OFFSET + offset,
				 write_buf, CHUNK_SIZE);
		if (rc != 0) {
			shell_error(sh, "Write failed at 0x%x: %d",
				    FLASH_TEST_OFFSET + offset, rc);
			goto cleanup;
		}
	}
	end_time = k_uptime_get();
	{
		uint64_t write_time = end_time - start_time;
		uint32_t write_speed = write_time > 0 ?
			(test_size / 1024 * 1000) / write_time : 0;
		shell_print(sh, "Write: %llu ms, %u KB/s", write_time, write_speed);
	}

	/* Read test + verify */
	shell_print(sh, "Reading %u KB...", test_size / 1024);
	start_time = k_uptime_get();
	for (uint32_t offset = 0; offset < test_size; offset += CHUNK_SIZE) {
		rc = flash_read(flash_dev, FLASH_TEST_OFFSET + offset,
				read_buf, CHUNK_SIZE);
		if (rc != 0) {
			shell_error(sh, "Read failed at 0x%x: %d",
				    FLASH_TEST_OFFSET + offset, rc);
			goto cleanup;
		}
		if (memcmp(write_buf, read_buf, CHUNK_SIZE) != 0) {
			shell_error(sh, "Verify failed at 0x%x",
				    FLASH_TEST_OFFSET + offset);
		}
	}
	end_time = k_uptime_get();
	{
		uint64_t read_time = end_time - start_time;
		uint32_t read_speed = read_time > 0 ?
			(test_size / 1024 * 1000) / read_time : 0;
		shell_print(sh, "Read:  %llu ms, %u KB/s (verified)", read_time, read_speed);
	}

cleanup:
	k_free(write_buf);
	k_free(read_buf);
	return 0;
}

/* Quick PASS/FAIL test: erase a 4 KiB block, write a 256 B pattern, read back,
 * verify. Result goes to the shell (not the OLED). Uses FLASH_TEST_OFFSET
 * (the unused OTA app slot in this no-MCUboot image) — the fuel-gauge
 * LittleFS at 0x130000 is left intact. */
static int cmd_flash_test(const struct shell *sh, size_t argc, char **argv)
{
	const struct device *flash_dev;
	uint8_t write_buf[256];
	uint8_t read_buf[256];
	int rc;

	ARG_UNUSED(argc);
	ARG_UNUSED(argv);

	flash_dev = DEVICE_DT_GET(DT_NODELABEL(spi_flash));
	if (!device_is_ready(flash_dev)) {
		shell_print(sh, "FAIL: SPI flash not ready");
		return -ENODEV;
	}

	for (int i = 0; i < sizeof(write_buf); i++) {
		write_buf[i] = (uint8_t)(i ^ 0xAA);
	}

	rc = flash_erase(flash_dev, FLASH_TEST_OFFSET, 4096);
	if (rc != 0) {
		shell_print(sh, "FAIL: erase %d", rc);
		return rc;
	}

	rc = flash_write(flash_dev, FLASH_TEST_OFFSET, write_buf, sizeof(write_buf));
	if (rc != 0) {
		shell_print(sh, "FAIL: write %d", rc);
		return rc;
	}

	rc = flash_read(flash_dev, FLASH_TEST_OFFSET, read_buf, sizeof(read_buf));
	if (rc != 0) {
		shell_print(sh, "FAIL: read %d", rc);
		return rc;
	}

	if (memcmp(write_buf, read_buf, sizeof(write_buf)) != 0) {
		shell_print(sh, "FAIL: verify mismatch");
		return -EIO;
	}

	shell_print(sh, "PASS: flash erase/write/read/verify OK");
	return 0;
}

SHELL_STATIC_SUBCMD_SET_CREATE(sub_flash,
	SHELL_CMD_ARG(speed, NULL, "Flash speed test [size_kb]", cmd_flash_speed, 1, 1),
	SHELL_CMD_ARG(test, NULL, "Flash PASS/FAIL test", cmd_flash_test, 1, 0),
	SHELL_SUBCMD_SET_END
);

SHELL_CMD_REGISTER(flash, &sub_flash, "SPI flash test commands", NULL);
```

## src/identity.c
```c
/*
 * Per-device identity for production-test (产测).
 * See identity.h for rationale.
 *
 * SPDX-License-Identifier: Apache-2.0
 */

#include <zephyr/kernel.h>
#include <zephyr/drivers/hwinfo.h>
#include <zephyr/shell/shell.h>
#include <zephyr/sys/printk.h>
#include <zephyr/bluetooth/bluetooth.h>
#include <zephyr/bluetooth/addr.h>
#include <stdio.h>
#include <string.h>

#include "identity.h"

/* Suffix length in hex digits.
 * 6 hex = 24-bit (~16M values; birthday-50% at ~4800 boards) — ample for a
 * 产测 line. For very large fleets change to 8 (32-bit) or 12; nRF5340 FICR
 * DEVICEID is 8 bytes (16 hex) so the source has plenty of entropy. */
#define IDENTITY_SUFFIX_HEX_LEN 6
#define IDENTITY_SUFFIX_BYTES   ((IDENTITY_SUFFIX_HEX_LEN + 1) / 2)

#define BLE_NAME_PREFIX "Clip_"
#define AP_SSID_PREFIX  "Clip_"

static char suffix[IDENTITY_SUFFIX_HEX_LEN + 1];
static char ble_name[sizeof(BLE_NAME_PREFIX) + IDENTITY_SUFFIX_HEX_LEN];
static char ap_ssid[sizeof(AP_SSID_PREFIX) + IDENTITY_SUFFIX_HEX_LEN];
static bool inited;

int identity_init(void)
{
	if (inited) {
		return 0;
	}

	uint8_t cid[16];
	ssize_t len = hwinfo_get_device_id(cid, sizeof(cid));

	/* Default-fill so the buffers are always valid even if hwinfo fails. */
	for (int i = 0; i < IDENTITY_SUFFIX_HEX_LEN; i++) {
		suffix[i] = '0';
	}
	suffix[IDENTITY_SUFFIX_HEX_LEN] = '\0';

	if (len > 0) {
		int off = (int)len > IDENTITY_SUFFIX_BYTES
				? (int)len - IDENTITY_SUFFIX_BYTES : 0;
		int sl = 0;
		for (int i = 0; i < IDENTITY_SUFFIX_BYTES && (off + i) < (int)len; i++) {
			sl += snprintk(suffix + sl, sizeof(suffix) - sl,
				       "%02X", cid[off + i]);
		}
		suffix[IDENTITY_SUFFIX_HEX_LEN] = '\0';
	}

	snprintk(ble_name, sizeof(ble_name), "%s%s", BLE_NAME_PREFIX, suffix);
	snprintk(ap_ssid, sizeof(ap_ssid), "%s%s", AP_SSID_PREFIX, suffix);

	inited = true;
	printk("[identity] suffix=%s ble=\"%s\" ap=\"%s\"\n",
	       suffix, ble_name, ap_ssid);
	return 0;
}

static void ensure(void)
{
	if (!inited) {
		(void)identity_init();
	}
}

const char *identity_suffix_get(void)
{
	ensure();
	return suffix;
}

const char *identity_ble_name_get(void)
{
	ensure();
	return ble_name;
}

const char *identity_ap_ssid_get(void)
{
	ensure();
	return ap_ssid;
}

/* `ident` — print the board's BLE name, BLE MAC, AP SSID and chip suffix.
 * Lets a产测 host read one serial line and know which board this is. */
static int cmd_ident(const struct shell *sh, size_t argc, char **argv)
{
	ARG_UNUSED(argc);
	ARG_UNUSED(argv);
	ensure();

	char addr_str[BT_ADDR_LE_STR_LEN] = "(n/a)";
	struct bt_le_oob oob;
	if (bt_le_oob_get_local(BT_ID_DEFAULT, &oob) == 0) {
		bt_addr_le_to_str(&oob.addr, addr_str, sizeof(addr_str));
	}

	shell_print(sh, "BLE name : %s", bt_get_name());
	shell_print(sh, "BLE MAC  : %s", addr_str);
	shell_print(sh, "AP SSID  : %s", ap_ssid);
	shell_print(sh, "suffix   : %s (chip_id last %d hex)",
		    suffix, IDENTITY_SUFFIX_HEX_LEN);
	return 0;
}

SHELL_CMD_REGISTER(ident, NULL,
		   "Show BLE name / MAC / AP SSID / chip suffix",
		   cmd_ident);
```

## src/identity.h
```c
/*
 * Per-device identity for production-test (产测).
 *
 * The reSpeaker Clip test firmware runs on many boards that may sit on the
 * same jig simultaneously. The BLE advertising name and WiFi AP SSID must
 * therefore carry a per-board token so a test host can lock RSSI/identity to
 * the device under test instead of seeing a sea of identical names.
 *
 * The token is the trailing hex of the nRF5340 FICR DEVICEID (read via
 * hwinfo). FICR is factory-programmed, so the token is stable across reboots
 * and re-flashes (it follows the silicon, not the firmware). Both the BLE
 * name and the AP SSID use the SAME token so a host reading either one can
 * correlate the board.
 */
#ifndef IDENTITY_H
#define IDENTITY_H

#include <stddef.h>

/* Compute and cache the per-device suffix from the chip id. Idempotent.
 * Safe to call multiple times; also called lazily by the getters. */
int identity_init(void);

/* Hex token derived from the chip id, e.g. "A1B2C3".
 * Length is IDENTITY_SUFFIX_HEX_LEN (6 by default; bump for larger fleets). */
const char *identity_suffix_get(void);

/* "Clip_Test_<suffix>" — set as the BLE advertising/connection name. */
const char *identity_ble_name_get(void);

/* "ClipTest_<suffix>" — used as the WiFi AP SSID. */
const char *identity_ap_ssid_get(void);

#endif /* IDENTITY_H */
```

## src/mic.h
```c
/*
 * Copyright (c) 2023 Nordic Semiconductor ASA
 *
 * SPDX-License-Identifier: LicenseRef-Nordic-5-Clause
 */

#ifndef MIC_H
#define MIC_H

int mic_init(void);
int mic_power_on(void);
int mic_power_off(void);

#endif /* MIC_H */
```
